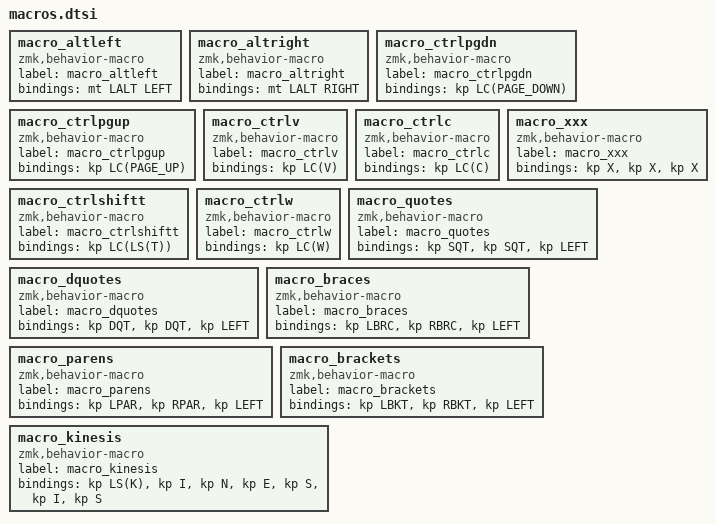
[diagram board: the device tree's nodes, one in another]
macro_altleft: macro_altleft{
compatible = "zmk,behavior-macro";
label = "macro_altleft";
#binding-cells = <0>;
bindings = <&mt LALT LEFT>;
};
macro_altright: macro_altright{
compatible = "zmk,behavior-macro";
label = "macro_altright";
#binding-cells = <0>;
bindings = <&mt LALT RIGHT>;
};
macro_ctrlpgdn: macro_ctrlpgdn{
compatible = "zmk,behavior-macro";
label = "macro_ctrlpgdn";
#binding-cells = <0>;
bindings = <&kp LC(PAGE_DOWN)>;
};
macro_ctrlpgup: macro_ctrlpgup{
compatible = "zmk,behavior-macro";
label = "macro_ctrlpgup";
#binding-cells = <0>;
bindings = <&kp LC(PAGE_UP)>;
};
macro_ctrlv: macro_ctrlv{
compatible = "zmk,behavior-macro";
label = "macro_ctrlv";
#binding-cells = <0>;
bindings = <&kp LC(V)>;
};
macro_ctrlc: macro_ctrlc{
compatible = "zmk,behavior-macro";
label = "macro_ctrlc";
#binding-cells = <0>;
bindings = <&kp LC(C)>;
};
macro_xxx: macro_xxx{
compatible = "zmk,behavior-macro";
label = "macro_xxx";
#binding-cells = <0>;
bindings = <&kp X>, <&kp X>, <&kp X>;
};
macro_ctrlshiftt: macro_ctrlshiftt{
compatible = "zmk,behavior-macro";
label = "macro_ctrlshiftt";
#binding-cells = <0>;
bindings = <&kp LC(LS(T))>;
};
macro_ctrlw: macro_ctrlw{
compatible = "zmk,behavior-macro";
label = "macro_ctrlw";
#binding-cells = <0>;
bindings = <&kp LC(W)>;
};
macro_quotes: macro_quotes{
compatible = "zmk,behavior-macro";
label = "macro_quotes";
#binding-cells = <0>;
bindings = <&kp SQT>, <&kp SQT>, <&kp LEFT>;
};
macro_dquotes: macro_dquotes{
compatible = "zmk,behavior-macro";
label = "macro_dquotes";
#binding-cells = <0>;
bindings = <&kp DQT>, <&kp DQT>, <&kp LEFT>;
};
macro_braces: macro_braces{
compatible = "zmk,behavior-macro";
label = "macro_braces";
#binding-cells = <0>;
bindings = <&kp LBRC>, <&kp RBRC>, <&kp LEFT>;
};
macro_parens: macro_parens{
compatible = "zmk,behavior-macro";
label = "macro_parens";
#binding-cells = <0>;
bindings = <&kp LPAR>, <&kp RPAR>, <&kp LEFT>;
};
macro_brackets: macro_brackets{
compatible = "zmk,behavior-macro";
label = "macro_brackets";
#binding-cells = <0>;
bindings = <&kp LBKT>, <&kp RBKT>, <&kp LEFT>;
};
macro_kinesis: macro_kinesis{
compatible = "zmk,behavior-macro";
label = "macro_kinesis";
#binding-cells = <0>;
bindings = <&kp LS(K)>, <&kp I>, <&kp N>, <&kp E>, <&kp S>, <&kp I>, <&kp S>;
};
